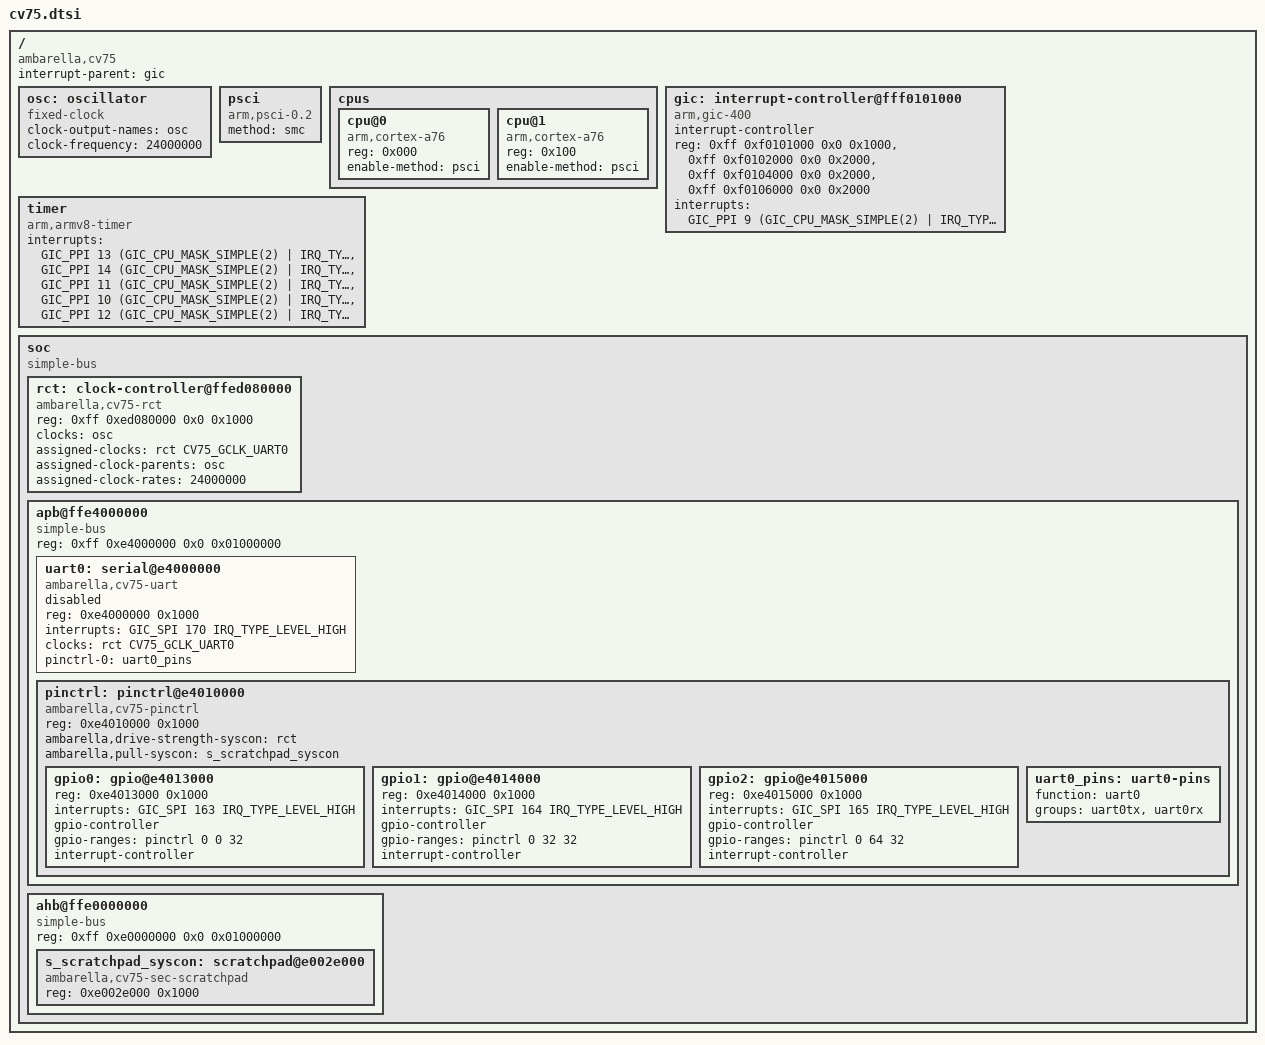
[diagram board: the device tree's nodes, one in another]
// SPDX-License-Identifier: GPL-2.0-or-later
/*
 * Ambarella CV75 SoC
 *
 * Boot peripheral: UART0 console.
 * Clocks: a single ambarella,cv75-rct provider.
 */

#include <dt-bindings/clock/ambarella,cv75-clock.h>
#include <dt-bindings/interrupt-controller/arm-gic.h>

/ {
	compatible = "ambarella,cv75";
	interrupt-parent = <&gic>;
	#address-cells = <2>;
	#size-cells = <2>;

	osc: oscillator {
		compatible = "fixed-clock";
		#clock-cells = <0>;
		clock-output-names = "osc";
		clock-frequency = <24000000>;
	};

	psci {
		compatible = "arm,psci-0.2";
		method = "smc";
	};

	cpus {
		#address-cells = <1>;
		#size-cells = <0>;

		cpu@0 {
			compatible = "arm,cortex-a76";
			device_type = "cpu";
			reg = <0x000>;
			enable-method = "psci";
		};

		cpu@1 {
			compatible = "arm,cortex-a76";
			device_type = "cpu";
			reg = <0x100>;
			enable-method = "psci";
		};
	};

	gic: interrupt-controller@fff0101000 {
		compatible = "arm,gic-400";
		#interrupt-cells = <3>;
		#address-cells = <0>;
		#size-cells = <1>;
		interrupt-controller;
		reg = <0xff 0xf0101000 0x0 0x1000>,
		      <0xff 0xf0102000 0x0 0x2000>,
		      <0xff 0xf0104000 0x0 0x2000>,
		      <0xff 0xf0106000 0x0 0x2000>;
		interrupts = <GIC_PPI 9 (GIC_CPU_MASK_SIMPLE(2) | IRQ_TYPE_LEVEL_HIGH)>;
	};

	timer {
		compatible = "arm,armv8-timer";
		interrupts = <GIC_PPI 13 (GIC_CPU_MASK_SIMPLE(2) | IRQ_TYPE_LEVEL_LOW)>,
			     <GIC_PPI 14 (GIC_CPU_MASK_SIMPLE(2) | IRQ_TYPE_LEVEL_LOW)>,
			     <GIC_PPI 11 (GIC_CPU_MASK_SIMPLE(2) | IRQ_TYPE_LEVEL_LOW)>,
			     <GIC_PPI 10 (GIC_CPU_MASK_SIMPLE(2) | IRQ_TYPE_LEVEL_LOW)>,
			     <GIC_PPI 12 (GIC_CPU_MASK_SIMPLE(2) | IRQ_TYPE_LEVEL_LOW)>;
	};

	soc {
		compatible = "simple-bus";
		#address-cells = <2>;
		#size-cells = <2>;
		ranges;

		/* Clock provider and shared system registers. */
		rct: clock-controller@ffed080000 {
			compatible = "ambarella,cv75-rct", "syscon";
			reg = <0xff 0xed080000 0x0 0x1000>;
			clocks = <&osc>;
			clock-names = "osc";
			#clock-cells = <1>;

			assigned-clocks = <&rct CV75_GCLK_UART0>;
			assigned-clock-parents = <&osc>;
			assigned-clock-rates = <24000000>;
		};

		apb@ffe4000000 {
			compatible = "simple-bus";
			#address-cells = <1>;
			#size-cells = <1>;
			reg = <0xff 0xe4000000 0x0 0x01000000>;
			ranges = <0xe4000000 0xff 0xe4000000 0x01000000>;

			uart0: serial@e4000000 {
				compatible = "ambarella,cv75-uart";
				reg = <0xe4000000 0x1000>;
				interrupts = <GIC_SPI 170 IRQ_TYPE_LEVEL_HIGH>;
				clocks = <&rct CV75_GCLK_UART0>;
				pinctrl-names = "default";
				pinctrl-0 = <&uart0_pins>;
				status = "disabled";
			};

			pinctrl: pinctrl@e4010000 {
				compatible = "ambarella,cv75-pinctrl";
				#address-cells = <1>;
				#size-cells = <1>;
				reg = <0xe4010000 0x1000>;
				ranges;
				ambarella,drive-strength-syscon = <&rct>;
				ambarella,pull-syscon = <&s_scratchpad_syscon>;

				gpio0: gpio@e4013000 {
					reg = <0xe4013000 0x1000>;
					interrupts = <GIC_SPI 163 IRQ_TYPE_LEVEL_HIGH>;
					gpio-controller;
					#gpio-cells = <2>;
					gpio-ranges = <&pinctrl 0 0 32>;
					interrupt-controller;
					#interrupt-cells = <2>;
				};

				gpio1: gpio@e4014000 {
					reg = <0xe4014000 0x1000>;
					interrupts = <GIC_SPI 164 IRQ_TYPE_LEVEL_HIGH>;
					gpio-controller;
					#gpio-cells = <2>;
					gpio-ranges = <&pinctrl 0 32 32>;
					interrupt-controller;
					#interrupt-cells = <2>;
				};

				gpio2: gpio@e4015000 {
					reg = <0xe4015000 0x1000>;
					interrupts = <GIC_SPI 165 IRQ_TYPE_LEVEL_HIGH>;
					gpio-controller;
					#gpio-cells = <2>;
					gpio-ranges = <&pinctrl 0 64 32>;
					interrupt-controller;
					#interrupt-cells = <2>;
				};

				uart0_pins: uart0-pins {
					function = "uart0";
					groups = "uart0tx", "uart0rx";
				};
			};
		};

		ahb@ffe0000000 {
			compatible = "simple-bus";
			#address-cells = <1>;
			#size-cells = <1>;
			reg = <0xff 0xe0000000 0x0 0x01000000>;
			ranges = <0xe0000000 0xff 0xe0000000 0x01000000>;

			s_scratchpad_syscon: scratchpad@e002e000 {
				compatible = "ambarella,cv75-sec-scratchpad", "syscon";
				reg = <0xe002e000 0x1000>;
			};
		};
	};
};
